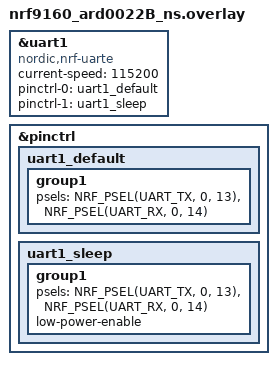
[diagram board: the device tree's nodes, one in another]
//
// Copyright (c) .NET Foundation and Contributors
// Portions Copyright (c) 2021 Nordic Semiconductor ASA
// See LICENSE file in the project root for full license information.
//

// 	current-speed = <115200>; 
//	current-speed = <921600>; 

// set UART1 out the Grove Connector
&uart1 {
	compatible = "nordic,nrf-uarte";
	current-speed = <115200>;
	status = "okay";
	pinctrl-0 = <&uart1_default>;
	pinctrl-1 = <&uart1_sleep>;
	pinctrl-names = "default", "sleep";
	/delete-property/ rts-pin;
	/delete-property/ cts-pin;
};

&pinctrl {

	uart1_default: uart1_default {
		group1 {
			psels = <NRF_PSEL(UART_TX, 0, 13)>,
				<NRF_PSEL(UART_RX, 0, 14)>;
		};
	};

	uart1_sleep: uart1_sleep {
		group1 {
			psels = <NRF_PSEL(UART_TX, 0, 13)>,
				<NRF_PSEL(UART_RX, 0, 14)>;
			low-power-enable;
		};
	};

};
